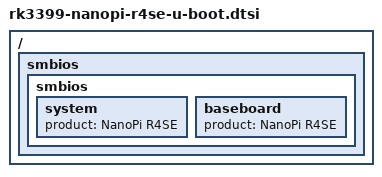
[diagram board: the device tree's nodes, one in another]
// SPDX-License-Identifier: GPL-2.0-or-later OR MIT

#include "rk3399-nanopi-r4s-u-boot.dtsi"

/ {
	smbios {
		smbios {
			system {
				product = "NanoPi R4SE";
			};

			baseboard {
				product = "NanoPi R4SE";
			};
		};
	};
};
